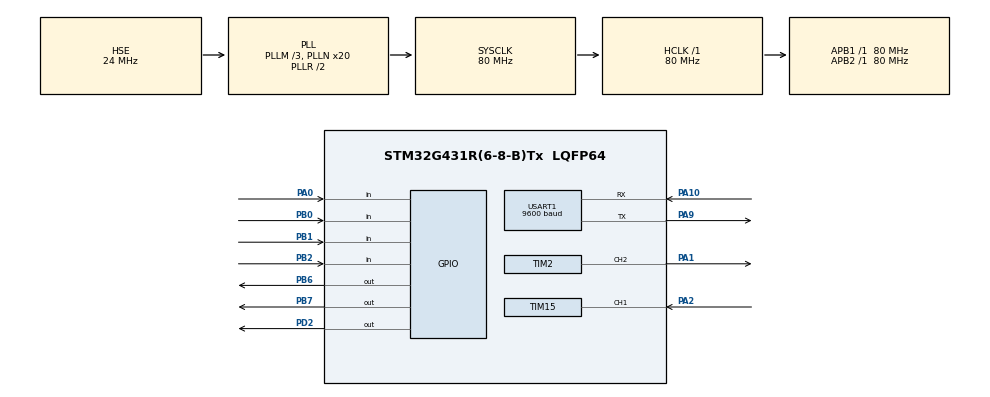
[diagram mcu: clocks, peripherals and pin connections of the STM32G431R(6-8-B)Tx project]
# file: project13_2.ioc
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Dma.Request0=USART1_RX
Dma.Request1=USART1_TX
Dma.USART1_RX.0.Direction=DMA_PERIPH_TO_MEMORY
Dma.USART1_RX.0.EventEnable=DISABLE
Dma.USART1_RX.0.Instance=DMA1_Channel1
Dma.USART1_RX.0.MemDataAlignment=DMA_MDATAALIGN_BYTE
Dma.USART1_RX.0.MemInc=DMA_MINC_ENABLE
Dma.USART1_RX.0.Mode=DMA_NORMAL
Dma.USART1_RX.0.PeriphDataAlignment=DMA_PDATAALIGN_BYTE
Dma.USART1_RX.0.PeriphInc=DMA_PINC_DISABLE
Dma.USART1_RX.0.Polarity=HAL_DMAMUX_REQ_GEN_RISING
Dma.USART1_RX.0.Priority=DMA_PRIORITY_LOW
Dma.USART1_RX.0.RequestNumber=1
Dma.USART1_RX.0.SignalID=NONE
Dma.USART1_RX.0.SyncEnable=DISABLE
Dma.USART1_RX.0.SyncPolarity=HAL_DMAMUX_SYNC_NO_EVENT
Dma.USART1_RX.0.SyncRequestNumber=1
Dma.USART1_RX.0.SyncSignalID=NONE
Dma.USART1_TX.1.Direction=DMA_MEMORY_TO_PERIPH
Dma.USART1_TX.1.EventEnable=DISABLE
Dma.USART1_TX.1.Instance=DMA1_Channel2
Dma.USART1_TX.1.MemDataAlignment=DMA_MDATAALIGN_BYTE
Dma.USART1_TX.1.MemInc=DMA_MINC_ENABLE
Dma.USART1_TX.1.Mode=DMA_NORMAL
Dma.USART1_TX.1.PeriphDataAlignment=DMA_PDATAALIGN_BYTE
Dma.USART1_TX.1.PeriphInc=DMA_PINC_DISABLE
Dma.USART1_TX.1.Polarity=HAL_DMAMUX_REQ_GEN_RISING
Dma.USART1_TX.1.Priority=DMA_PRIORITY_LOW
Dma.USART1_TX.1.RequestNumber=1
Dma.USART1_TX.1.SignalID=NONE
Dma.USART1_TX.1.SyncEnable=DISABLE
Dma.USART1_TX.1.SyncPolarity=HAL_DMAMUX_SYNC_NO_EVENT
Dma.USART1_TX.1.SyncRequestNumber=1
Dma.USART1_TX.1.SyncSignalID=NONE
Mcu.Family=STM32G4
Mcu.Name=STM32G431R(6-8-B)Tx
Mcu.Package=LQFP64
NVIC.DMA1_Channel1_IRQn=true\:0\:0\:false\:false\:true\:false\:true
NVIC.DMA1_Channel2_IRQn=true\:0\:0\:false\:false\:true\:false\:true
NVIC.PriorityGroup=NVIC_PRIORITYGROUP_4
NVIC.TIM1_BRK_TIM15_IRQn=true\:0\:0\:false\:false\:true\:true\:true
NVIC.TIM2_IRQn=true\:0\:0\:false\:false\:true\:true\:true
NVIC.USART1_IRQn=true\:0\:0\:false\:false\:true\:true\:true
PA0.Signal=GPIO_Input
PA1.Signal=S_TIM2_CH2
PA10.Mode=Asynchronous
PA10.Signal=USART1_RX
PA2.Signal=S_TIM15_CH1
PA9.Mode=Asynchronous
PA9.Signal=USART1_TX
PB0.Signal=GPIO_Input
PB1.Signal=GPIO_Input
PB2.Signal=GPIO_Input
PB6.PinState=GPIO_PIN_SET
PB6.Signal=GPIO_Output
PB7.PinState=GPIO_PIN_SET
PB7.Signal=GPIO_Output
PD2.PinState=GPIO_PIN_SET
PD2.Signal=GPIO_Output
PF0-OSC_IN.Mode=HSE-External-Oscillator
PF0-OSC_IN.Signal=RCC_OSC_IN
PF1-OSC_OUT.Mode=HSE-External-Oscillator
PF1-OSC_OUT.Signal=RCC_OSC_OUT
ProjectManager.HeapSize=0x200
ProjectManager.StackSize=0x400
ProjectManager.TargetToolchain=MDK-ARM V5.27
RCC.ADC12Freq_Value=80000000
RCC.AHBFreq_Value=80000000
RCC.APB1Freq_Value=80000000
RCC.APB1TimFreq_Value=80000000
RCC.APB2Freq_Value=80000000
RCC.APB2TimFreq_Value=80000000
RCC.CortexFreq_Value=80000000
RCC.EXTERNAL_CLOCK_VALUE=12288000
RCC.HCLKFreq_Value=80000000
RCC.HSE_VALUE=24000000
RCC.HSI48_VALUE=48000000
RCC.HSI_VALUE=16000000
RCC.LSE_VALUE=32768
RCC.PLLM=RCC_PLLM_DIV3
RCC.PLLN=20
RCC.PLLSourceVirtual=RCC_PLLSOURCE_HSE
RCC.SYSCLKFreq_VALUE=80000000
RCC.SYSCLKSource=RCC_SYSCLKSOURCE_PLLCLK
RCC.USBFreq_Value=80000000
RCC.VCOOutputFreq_Value=160000000
SH.S_TIM15_CH1.0=TIM15_CH1,PWM_Input_1
SH.S_TIM2_CH2.0=TIM2_CH2,PWM Generation2 CH2
TIM15.AutoReloadPreload=TIM_AUTORELOAD_PRELOAD_ENABLE
TIM15.PeriodNoDither=65535
TIM15.Prescaler=79
TIM2.AutoReloadPreload=TIM_AUTORELOAD_PRELOAD_ENABLE
TIM2.Channel-PWM\ Generation2\ CH2=TIM_CHANNEL_2
TIM2.PeriodNoDither=999
TIM2.Prescaler=79
TIM2.PulseNoDither_2=50
USART1.BaudRate=9600
USART1.VirtualMode-Asynchronous=VM_ASYNC
VP_SYS_VS_DBSignals.Mode=DisableDeadBatterySignals
VP_TIM15_VS_ClockSourceINT.Mode=Internal
VP_TIM2_VS_ClockSourceINT.Mode=Internal
board=custom

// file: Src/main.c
/* USER CODE BEGIN Header */
/**
  ******************************************************************************
  * @file           : main.c
  * @brief          : Main program body
  ******************************************************************************
  * @attention
  *
  * <h2><center>&copy; Copyright (c) 2022 STMicroelectronics.
  * All rights reserved.</center></h2>
  *
  * This software component is licensed by ST under BSD 3-Clause license,
  * the "License"; You may not use this file except in compliance with the
  * License. You may obtain a copy of the License at:
  *                        opensource.org/licenses/BSD-3-Clause
  *
  ******************************************************************************
  */
/* USER CODE END Header */

#include "main.h"
#include "dma.h"
#include "tim.h"
#include "usart.h"
#include "gpio.h"

void SystemClock_Config(void);

int main(void)
{

  /* MCU Configuration--------------------------------------------------------*/

  /* Reset of all peripherals, Initializes the Flash interface and the Systick. */
  HAL_Init();

  /* Configure the system clock */
  SystemClock_Config();

  /* Initialize all configured peripherals */
  MX_GPIO_Init();
  MX_DMA_Init();
  MX_TIM2_Init();
  MX_TIM15_Init();
  MX_USART1_UART_Init();
  /* USER CODE BEGIN 2 */
   task_init();
  /* USER CODE END 2 */

  /* Infinite loop */
  while (1)
  {

    /* USER CODE BEGIN 3 */
		project();
  }
  /* USER CODE END 3 */
}

void SystemClock_Config(void)
{
  RCC_OscInitTypeDef RCC_OscInitStruct = {0};
  RCC_ClkInitTypeDef RCC_ClkInitStruct = {0};
  RCC_PeriphCLKInitTypeDef PeriphClkInit = {0};

  /** Configure the main internal regulator output voltage
  */
  HAL_PWREx_ControlVoltageScaling(PWR_REGULATOR_VOLTAGE_SCALE1);
  /** Initializes the CPU, AHB and APB busses clocks
  */
  RCC_OscInitStruct.OscillatorType = RCC_OSCILLATORTYPE_HSE;
  RCC_OscInitStruct.HSEState = RCC_HSE_ON;
  RCC_OscInitStruct.PLL.PLLState = RCC_PLL_ON;
  RCC_OscInitStruct.PLL.PLLSource = RCC_PLLSOURCE_HSE;
  RCC_OscInitStruct.PLL.PLLM = RCC_PLLM_DIV3;
  RCC_OscInitStruct.PLL.PLLN = 20;
  RCC_OscInitStruct.PLL.PLLP = RCC_PLLP_DIV2;
  RCC_OscInitStruct.PLL.PLLQ = RCC_PLLQ_DIV2;
  RCC_OscInitStruct.PLL.PLLR = RCC_PLLR_DIV2;
  if (HAL_RCC_OscConfig(&RCC_OscInitStruct) != HAL_OK)
  {
    Error_Handler();
  }
  /** Initializes the CPU, AHB and APB busses clocks
  */
  RCC_ClkInitStruct.ClockType = RCC_CLOCKTYPE_HCLK|RCC_CLOCKTYPE_SYSCLK
                              |RCC_CLOCKTYPE_PCLK1|RCC_CLOCKTYPE_PCLK2;
  RCC_ClkInitStruct.SYSCLKSource = RCC_SYSCLKSOURCE_PLLCLK;
  RCC_ClkInitStruct.AHBCLKDivider = RCC_SYSCLK_DIV1;
  RCC_ClkInitStruct.APB1CLKDivider = RCC_HCLK_DIV1;
  RCC_ClkInitStruct.APB2CLKDivider = RCC_HCLK_DIV1;

  if (HAL_RCC_ClockConfig(&RCC_ClkInitStruct, FLASH_LATENCY_3) != HAL_OK)
  {
    Error_Handler();
  }
  /** Initializes the peripherals clocks
  */
  PeriphClkInit.PeriphClockSelection = RCC_PERIPHCLK_USART1;
  PeriphClkInit.Usart1ClockSelection = RCC_USART1CLKSOURCE_PCLK2;
  if (HAL_RCCEx_PeriphCLKConfig(&PeriphClkInit) != HAL_OK)
  {
    Error_Handler();
  }
}

void Error_Handler(void)
{
}

/************************ (C) COPYRIGHT STMicroelectronics *****END OF FILE****/
